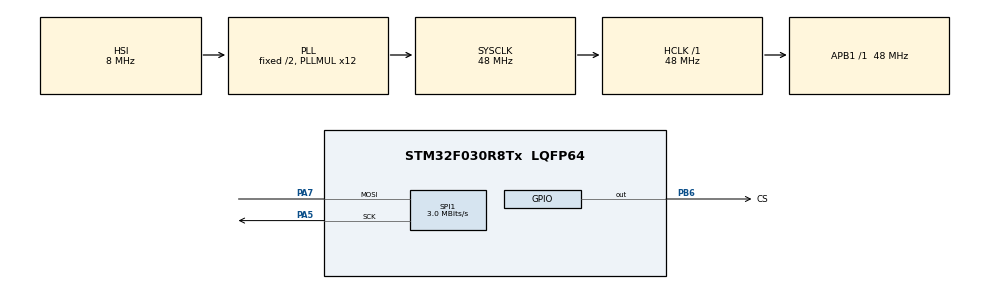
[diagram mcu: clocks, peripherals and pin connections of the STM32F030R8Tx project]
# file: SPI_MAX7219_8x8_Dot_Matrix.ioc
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Mcu.Family=STM32F0
Mcu.Name=STM32F030R8Tx
Mcu.Package=LQFP64
PA13.Mode=Serial_Wire
PA13.Signal=SYS_SWDIO
PA14.Mode=Serial_Wire
PA14.Signal=SYS_SWCLK
PA5.Mode=Simplex_Bidirectional_Master
PA5.Signal=SPI1_SCK
PA7.Mode=Simplex_Bidirectional_Master
PA7.Signal=SPI1_MOSI
PB6.GPIO_Label=CS
PB6.GPIO_Speed=GPIO_SPEED_FREQ_MEDIUM
PB6.PinState=GPIO_PIN_RESET
PB6.Signal=GPIO_Output
ProjectManager.HeapSize=0x200
ProjectManager.StackSize=0x400
ProjectManager.TargetToolchain=STM32CubeIDE
RCC.AHBFreq_Value=48000000
RCC.APB1Freq_Value=48000000
RCC.APB1TimFreq_Value=48000000
RCC.HCLKFreq_Value=48000000
RCC.PLLMUL=RCC_PLL_MUL12
RCC.SYSCLKFreq_VALUE=48000000
RCC.SYSCLKSource=RCC_SYSCLKSOURCE_PLLCLK
SPI1.BaudRatePrescaler=SPI_BAUDRATEPRESCALER_16
SPI1.CLKPolarity=SPI_POLARITY_LOW
SPI1.CalculateBaudRate=3.0 MBits/s
SPI1.DataSize=SPI_DATASIZE_8BIT
SPI1.Direction=SPI_DIRECTION_1LINE
SPI1.Mode=SPI_MODE_MASTER
SPI1.VirtualType=VM_MASTER
board=NUCLEO-F030R8

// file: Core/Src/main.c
/* USER CODE BEGIN Header */
/**
 ******************************************************************************
 * @file           : main.c
 * @brief          : Main program body
 ******************************************************************************
 * @attention
 *
 * Copyright (c) 2026 STMicroelectronics.
 * All rights reserved.
 *
 * This software is licensed under terms that can be found in the LICENSE file
 * in the root directory of this software component.
 * If no LICENSE file comes with this software, it is provided AS-IS.
 *
 ******************************************************************************
 */
/* USER CODE END Header */
#include "main.h"

/* USER CODE BEGIN Includes */
#include "max7219.h"//header dosyasi dahil edildi
/* USER CODE END Includes */

SPI_HandleTypeDef hspi1;

void SystemClock_Config(void);
static void MX_GPIO_Init(void);
static void MX_SPI1_Init(void);

int main(void) {

	/* MCU Configuration--------------------------------------------------------*/

	/* Reset of all peripherals, Initializes the Flash interface and the Systick. */
	HAL_Init();

	/* Configure the system clock */
	SystemClock_Config();

	/* Initialize all configured peripherals */
	MX_GPIO_Init();
	MX_SPI1_Init();
	/* USER CODE BEGIN 2 */
	//const uint8_t smiley[8] = { 0x00, 0x18, 0x24, 0x42, 0x42, 0x7e, 0x42, 0x00//gulumseme deseni yazdirildi deneme icin
	//};

	MAX7219_Init(&hspi1);//baslangic fonksiyonu calistirildi
	//MAX7219_Display_Matrix(&hspi1, letters[0]);

	//MAX7219_Display_Matrix(&hspi1, smiley);
	/* USER CODE END 2 */

	/* Infinite loop */
	while (1) {

		/* USER CODE BEGIN 3 */

		 for (int i = 0; i < 10; i++) {//numaralar matrisini sirayla ekrana basmak icin yazildi
			 MAX7219_Display_Matrix(&hspi1, numbers[i]);
			 HAL_Delay(300);

		 }

		 for (int i = 0; i < 26; i++) {//harler matrisini sirayla ekrana basmak icin yazildi
		 MAX7219_Display_Matrix(&hspi1, letters[i]);
		 HAL_Delay(300);

		 }

	}
	/* USER CODE END 3 */
}

void SystemClock_Config(void) {
	RCC_OscInitTypeDef RCC_OscInitStruct = { 0 };
	RCC_ClkInitTypeDef RCC_ClkInitStruct = { 0 };

	/** Initializes the RCC Oscillators according to the specified parameters
	 * in the RCC_OscInitTypeDef structure.
	 */
	RCC_OscInitStruct.OscillatorType = RCC_OSCILLATORTYPE_HSI;
	RCC_OscInitStruct.HSIState = RCC_HSI_ON;
	RCC_OscInitStruct.HSICalibrationValue = RCC_HSICALIBRATION_DEFAULT;
	RCC_OscInitStruct.PLL.PLLState = RCC_PLL_ON;
	RCC_OscInitStruct.PLL.PLLSource = RCC_PLLSOURCE_HSI;
	RCC_OscInitStruct.PLL.PLLMUL = RCC_PLL_MUL12;
	RCC_OscInitStruct.PLL.PREDIV = RCC_PREDIV_DIV1;
	if (HAL_RCC_OscConfig(&RCC_OscInitStruct) != HAL_OK) {
		Error_Handler();
	}

	/** Initializes the CPU, AHB and APB buses clocks
	 */
	RCC_ClkInitStruct.ClockType = RCC_CLOCKTYPE_HCLK | RCC_CLOCKTYPE_SYSCLK
			| RCC_CLOCKTYPE_PCLK1;
	RCC_ClkInitStruct.SYSCLKSource = RCC_SYSCLKSOURCE_PLLCLK;
	RCC_ClkInitStruct.AHBCLKDivider = RCC_SYSCLK_DIV1;
	RCC_ClkInitStruct.APB1CLKDivider = RCC_HCLK_DIV1;

	if (HAL_RCC_ClockConfig(&RCC_ClkInitStruct, FLASH_LATENCY_1) != HAL_OK) {
		Error_Handler();
	}
}

static void MX_SPI1_Init(void) {

	/* SPI1 parameter configuration*/
	hspi1.Instance = SPI1;
	hspi1.Init.Mode = SPI_MODE_MASTER;
	hspi1.Init.Direction = SPI_DIRECTION_1LINE;
	hspi1.Init.DataSize = SPI_DATASIZE_8BIT;
	hspi1.Init.CLKPolarity = SPI_POLARITY_LOW;
	hspi1.Init.CLKPhase = SPI_PHASE_1EDGE;
	hspi1.Init.NSS = SPI_NSS_SOFT;
	hspi1.Init.BaudRatePrescaler = SPI_BAUDRATEPRESCALER_16;
	hspi1.Init.FirstBit = SPI_FIRSTBIT_MSB;
	hspi1.Init.TIMode = SPI_TIMODE_DISABLE;
	hspi1.Init.CRCCalculation = SPI_CRCCALCULATION_DISABLE;
	hspi1.Init.CRCPolynomial = 7;
	hspi1.Init.CRCLength = SPI_CRC_LENGTH_DATASIZE;
	hspi1.Init.NSSPMode = SPI_NSS_PULSE_ENABLE;
	if (HAL_SPI_Init(&hspi1) != HAL_OK) {
		Error_Handler();
	}

}

static void MX_GPIO_Init(void) {
	GPIO_InitTypeDef GPIO_InitStruct = { 0 };

	/* GPIO Ports Clock Enable */
	__HAL_RCC_GPIOA_CLK_ENABLE();
	__HAL_RCC_GPIOB_CLK_ENABLE();

	/*Configure GPIO pin Output Level */
	HAL_GPIO_WritePin(CS_GPIO_Port, CS_Pin, GPIO_PIN_RESET);

	/*Configure GPIO pin : CS_Pin */
	GPIO_InitStruct.Pin = CS_Pin;
	GPIO_InitStruct.Mode = GPIO_MODE_OUTPUT_PP;
	GPIO_InitStruct.Pull = GPIO_NOPULL;
	GPIO_InitStruct.Speed = GPIO_SPEED_FREQ_MEDIUM;
	HAL_GPIO_Init(CS_GPIO_Port, &GPIO_InitStruct);

}

void Error_Handler(void) {
	__disable_irq();
	while (1) {
	}
}
